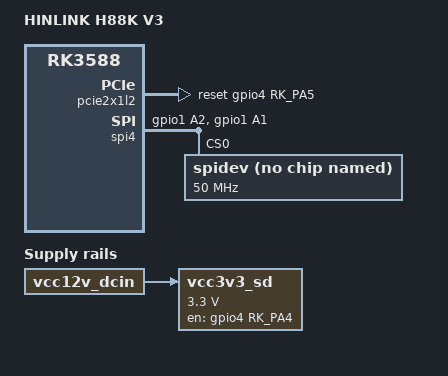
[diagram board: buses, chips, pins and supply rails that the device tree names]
// SPDX-License-Identifier: (GPL-2.0+ OR MIT)
/*
 * HinLink OPC-H88K V3 —— HinLink 适配 for immortalwrt
 *
 * 本文件基于 istoreos/istoreos 的 rk3588-h88k-v3.dts，
 * 仅追加头部说明，未改动硬件配置。
 *
 * ★ 依赖：rk3588-hinlink.dtsi（iStoreOS 私有，immortalwrt 6.18 内核中没有）
 *   必须一并移植，否则编译失败。来源：
 *   https://github.com/istoreos/istoreos
 *     target/linux/rockchip/dts/rk3588/rk3588-hinlink.dtsi
 *   该dtsi 还需下列 iStoreOS 私有 dtsi（在同目录下）：
 *     rk3588-hdmirx.dtsi  rk3588-ramoops.dtsi  rk3588-rk806-single.dtsi
 *     rk3588s-ip.dtsi  rk3588s-ip-supply.dtsi
 *     rk3588s-crypto.dtsi  rk3588s-gpu.dtsi  rk3588s-npu.dtsi  rk3588s-vpu.dtsi
 *
 * 硬件要点：
 *   - pcie2x1l2 + RTL8125 2.5G，&spi4 接 ST7789V 屏
 *   - eth_order 显式固定 NIC 与 GMAC 枚举顺序（作者遇到过顺序不稳定） */
/*
 * Copyright (c) 2023 iStoreOS
 * (https://www.istoreos.com)
 *
 * Copyright (c) 2022 Rockchip Electronics Co., Ltd.
 *
 */

/dts-v1/;

#include "rk3588-hinlink.dtsi"

/ {
	model = "HINLINK H88K V3";
	compatible = "hinlink,h88k-v3", "rockchip,rk3588";
	eth_order = "0004:*1:00.0,0003:*1:00.0,fe1b0000.ethernet";

	vcc3v3_sd: vcc3v3-sd-regulator {
		compatible = "regulator-fixed";
		enable-active-high;
		regulator-always-on;
		regulator-boot-on;
		gpios = <&gpio4 RK_PA4 GPIO_ACTIVE_HIGH>;
		regulator-min-microvolt = <3300000>;
		regulator-max-microvolt = <3300000>;
		regulator-name = "vcc3v3_sd";
		vin-supply = <&vcc12v_dcin>;
	};
};

// combphy0_ps
&pcie2x1l2 {
	// rtl8125
	reset-gpios = <&gpio4 RK_PA5 GPIO_ACTIVE_HIGH>;
	status = "okay";
};

// lcd
&spi4 {
	status = "okay";
	pinctrl-0 = <&spi4m2_cs0 &spi4m2_out_pins>;
	spidev@0 {
		compatible = "rockchip,spidev";
		reg = <0>;
		spi-max-frequency = <50000000>;
		status = "okay";
		pinctrl-names = "default";
		pinctrl-0 = <&spi_lcd_pins>;
	};
};

&pinctrl {
	spi4 {
		/omit-if-no-ref/
		spi4m2_out_pins: spi4m2-out-pins {
			rockchip,pins =
				/* spi4_clk_m2 */
				<1 RK_PA2 8 &pcfg_pull_up_drv_level_6>,
				/* spi4_mosi_m2 */
				<1 RK_PA1 8 &pcfg_pull_up_drv_level_6>;
		};
	};
	lcd {
		/omit-if-no-ref/
		spi_lcd_pins: spi-lcd-pins {
			rockchip,pins =
				<1 RK_PA4 RK_FUNC_GPIO &pcfg_pull_none>;
		};
	};
};
